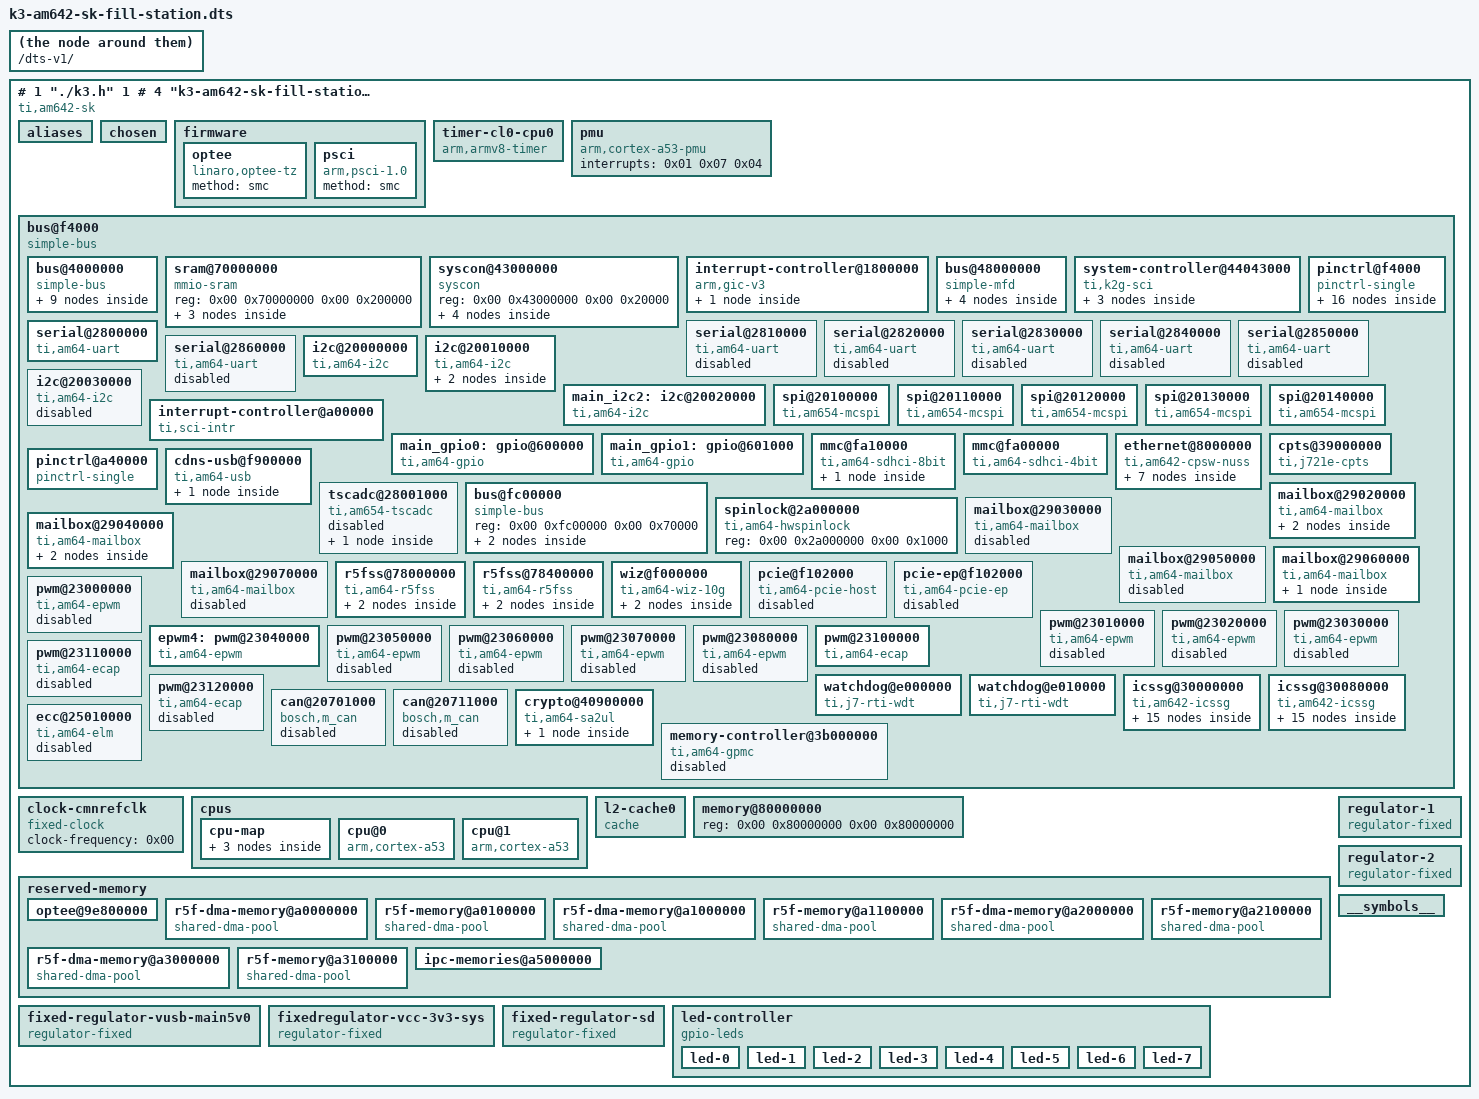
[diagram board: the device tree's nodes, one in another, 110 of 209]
# 1 "k3-am642-sk-fill-station.dts"
# 1 "<built-in>" 1
# 1 "<built-in>" 3
# 10 "<built-in>" 3
# 1 "<command line>" 1
# 1 "<built-in>" 2
# 1 "k3-am642-sk-fill-station.dts" 2
/dts-v1/;

# 1 "./k3.h" 1
# 4 "k3-am642-sk-fill-station.dts" 2

/ {
 model = "Texas Instruments AM642 SK";
 compatible = "ti,am642-sk", "ti,am642";
 interrupt-parent = <0x01>;
 #address-cells = <0x02>;
 #size-cells = <0x02>;

 aliases {
  serial0 = "/bus@f4000/bus@4000000/serial@4a00000";
  serial1 = "/bus@f4000/bus@4000000/serial@4a10000";
  serial2 = "/bus@f4000/serial@2800000";
  serial3 = "/bus@f4000/serial@2810000";
  serial4 = "/bus@f4000/serial@2820000";
  serial5 = "/bus@f4000/serial@2830000";
  serial6 = "/bus@f4000/serial@2840000";
  serial7 = "/bus@f4000/serial@2850000";
  serial8 = "/bus@f4000/serial@2860000";
  ethernet0 = "/bus@f4000/ethernet@8000000/ethernet-ports/port@1";
  ethernet1 = "/bus@f4000/ethernet@8000000/ethernet-ports/port@2";
  mmc0 = "/bus@f4000/mmc@fa10000";
  mmc1 = "/bus@f4000/mmc@fa00000";
 };

 chosen {
  stdout-path = "serial2:115200n8";
  bootargs = "console=ttyS2,115200n8 earlycon=ns16550a,mmio32,0x02800000";
 };

 firmware {

  optee {
   compatible = "linaro,optee-tz";
   method = "smc";
  };

  psci {
   compatible = "arm,psci-1.0";
   method = "smc";
   phandle = <0x3f>;
  };
 };

 timer-cl0-cpu0 {
  compatible = "arm,armv8-timer";
  interrupts = <0x01 0x0d 0x08 0x01 0x0e 0x08 0x01 0x0b 0x08 0x01 0x0a 0x08>;
  phandle = <0x40>;
 };

 pmu {
  compatible = "arm,cortex-a53-pmu";
  interrupts = <0x01 0x07 0x04>;
  phandle = <0x41>;
 };

 bus@f4000 {
  compatible = "simple-bus";
  #address-cells = <0x02>;
  #size-cells = <0x02>;
  ranges = <0x00 0xf4000 0x00 0xf4000 0x00 0x2d0 0x00 0x420000 0x00 0x420000 0x00 0x1000 0x00 0x600000 0x00 0x600000 0x00 0x1100 0x00 0xa40000 0x00 0xa40000 0x00 0x800 0x00 0x1000000 0x00 0x1000000 0x00 0x2330400 0x00 0x8000000 0x00 0x8000000 0x00 0x200000 0x00 0xd000000 0x00 0xd000000 0x00 0x800000 0x00 0xe000000 0x00 0xe000000 0x00 0x100 0x00 0xe010000 0x00 0xe010000 0x00 0x100 0x00 0xf000000 0x00 0xf000000 0x00 0xc44200 0x00 0x20000000 0x00 0x20000000 0x00 0xa008000 0x00 0x30000000 0x00 0x30000000 0x00 0xbc100 0x00 0x37000000 0x00 0x37000000 0x00 0x40000 0x00 0x39000000 0x00 0x39000000 0x00 0x400 0x00 0x3b000000 0x00 0x3b000000 0x00 0x400 0x00 0x3cd00000 0x00 0x3cd00000 0x00 0x200 0x00 0x3f004000 0x00 0x3f004000 0x00 0x400 0x00 0x40900000 0x00 0x40900000 0x00 0x30000 0x00 0x43000000 0x00 0x43000000 0x00 0x20000 0x00 0x44043000 0x00 0x44043000 0x00 0xfe0 0x00 0x48000000 0x00 0x48000000 0x00 0x6400000 0x00 0x50000000 0x00 0x50000000 0x00 0x8000000 0x00 0x60000000 0x00 0x60000000 0x00 0x8000000 0x00 0x68000000 0x00 0x68000000 0x00 0x8000000 0x00 0x70000000 0x00 0x70000000 0x00 0x200000 0x00 0x78000000 0x00 0x78000000 0x00 0x800000 0x01 0x00 0x01 0x00 0x00 0x310000 0x06 0x00 0x06 0x00 0x01 0x00 0x05 0x00 0x05 0x00 0x01 0x00 0x00 0x4000000 0x00 0x4000000 0x00 0x1ff1400>;
  phandle = <0x42>;

  bus@4000000 {
   compatible = "simple-bus";
   #address-cells = <0x02>;
   #size-cells = <0x02>;
   ranges = <0x00 0x4000000 0x00 0x4000000 0x00 0x1ff1400>;
   phandle = <0x43>;

   serial@4a00000 {
    compatible = "ti,am64-uart", "ti,am654-uart";
    reg = <0x00 0x4a00000 0x00 0x100>;
    interrupts = <0x00 0xb9 0x04>;
    current-speed = <0x1c200>;
    power-domains = <0x02 0x95 0x01>;
    clocks = <0x03 0x95 0x00>;
    clock-names = "fclk";
    status = "disabled";
    phandle = <0x44>;
   };

   serial@4a10000 {
    compatible = "ti,am64-uart", "ti,am654-uart";
    reg = <0x00 0x4a10000 0x00 0x100>;
    interrupts = <0x00 0xba 0x04>;
    current-speed = <0x1c200>;
    power-domains = <0x02 0xa0 0x01>;
    clocks = <0x03 0xa0 0x00>;
    clock-names = "fclk";
    status = "disabled";
    phandle = <0x45>;
   };

   i2c@4900000 {
    compatible = "ti,am64-i2c", "ti,omap4-i2c";
    reg = <0x00 0x4900000 0x00 0x100>;
    interrupts = <0x00 0x6b 0x04>;
    #address-cells = <0x01>;
    #size-cells = <0x00>;
    power-domains = <0x02 0x6a 0x01>;
    clocks = <0x03 0x6a 0x02>;
    clock-names = "fck";
    status = "disabled";
    phandle = <0x46>;
   };

   i2c@4910000 {
    compatible = "ti,am64-i2c", "ti,omap4-i2c";
    reg = <0x00 0x4910000 0x00 0x100>;
    interrupts = <0x00 0x6c 0x04>;
    #address-cells = <0x01>;
    #size-cells = <0x00>;
    power-domains = <0x02 0x6b 0x01>;
    clocks = <0x03 0x6b 0x02>;
    clock-names = "fck";
    status = "disabled";
    phandle = <0x47>;
   };

   spi@4b00000 {
    compatible = "ti,am654-mcspi", "ti,omap4-mcspi";
    reg = <0x00 0x4b00000 0x00 0x400>;
    interrupts = <0x00 0xb0 0x04>;
    #address-cells = <0x01>;
    #size-cells = <0x00>;
    power-domains = <0x02 0x93 0x01>;
    clocks = <0x03 0x93 0x00>;
    status = "disabled";
    phandle = <0x48>;
   };

   spi@4b10000 {
    compatible = "ti,am654-mcspi", "ti,omap4-mcspi";
    reg = <0x00 0x4b10000 0x00 0x400>;
    interrupts = <0x00 0xb1 0x04>;
    #address-cells = <0x01>;
    #size-cells = <0x00>;
    power-domains = <0x02 0x94 0x01>;
    clocks = <0x03 0x94 0x00>;
    status = "disabled";
    phandle = <0x49>;
   };

   interrupt-controller@4210000 {
    compatible = "ti,sci-intr";
    reg = <0x00 0x4210000 0x00 0x200>;
    ti,intr-trigger-type = <0x01>;
    interrupt-controller;
    interrupt-parent = <0x01>;
    #interrupt-cells = <0x01>;
    ti,sci = <0x04>;
    ti,sci-dev-id = <0x05>;
    ti,interrupt-ranges = <0x00 0x68 0x04>;
    phandle = <0x05>;
   };

   gpio@4201000 {
    compatible = "ti,am64-gpio", "ti,keystone-gpio";
    reg = <0x00 0x4201000 0x00 0x100>;
    gpio-controller;
    #gpio-cells = <0x02>;
    interrupt-parent = <0x05>;
    interrupts = <0x1e 0x1f>;
    interrupt-controller;
    #interrupt-cells = <0x02>;
    ti,ngpio = <0x17>;
    ti,davinci-gpio-unbanked = <0x00>;
    power-domains = <0x02 0x4f 0x01>;
    clocks = <0x03 0x4f 0x00>;
    clock-names = "gpio";
    status = "reserved";
    phandle = <0x4a>;
   };

   pinctrl@4084000 {
    compatible = "pinctrl-single";
    reg = <0x00 0x4084000 0x00 0x84>;
    #pinctrl-cells = <0x01>;
    pinctrl-single,register-width = <0x20>;
    pinctrl-single,function-mask = <0xffffffff>;
    phandle = <0x4b>;
   };
  };

  sram@70000000 {
   compatible = "mmio-sram";
   reg = <0x00 0x70000000 0x00 0x200000>;
   #address-cells = <0x01>;
   #size-cells = <0x01>;
   ranges = <0x00 0x00 0x70000000 0x200000>;
   phandle = <0x4c>;

   tfa-sram@1c0000 {
    reg = <0x1c0000 0x20000>;
   };

   dmsc-sram@1e0000 {
    reg = <0x1e0000 0x1c000>;
   };

   sproxy-sram@1fc000 {
    reg = <0x1fc000 0x4000>;
   };
  };

  syscon@43000000 {
   compatible = "syscon", "simple-mfd";
   reg = <0x00 0x43000000 0x00 0x20000>;
   #address-cells = <0x01>;
   #size-cells = <0x01>;
   ranges = <0x00 0x00 0x43000000 0x20000>;
   phandle = <0x16>;

   mux-controller {
    compatible = "mmio-mux";
    #mux-control-cells = <0x01>;
    mux-reg-masks = <0x4080 0x03>;
    idle-states = <0x01>;
    phandle = <0x4d>;
   };

   chipid@14 {
    compatible = "ti,am654-chipid";
    reg = <0x14 0x04>;
   };

   phy@4044 {
    compatible = "ti,am654-phy-gmii-sel";
    reg = <0x4044 0x08>;
    #phy-cells = <0x01>;
    phandle = <0x15>;
   };

   clock@4140 {
    compatible = "ti,am64-epwm-tbclk", "syscon";
    reg = <0x4130 0x04>;
    #clock-cells = <0x01>;
    phandle = <0x2f>;
   };
  };

  interrupt-controller@1800000 {
   compatible = "arm,gic-v3";
   #address-cells = <0x02>;
   #size-cells = <0x02>;
   ranges;
   #interrupt-cells = <0x03>;
   interrupt-controller;
   reg = <0x00 0x1800000 0x00 0x10000 0x00 0x1840000 0x00 0xc0000 0x01 0x00 0x00 0x2000 0x01 0x10000 0x00 0x1000 0x01 0x20000 0x00 0x2000>;
   interrupts = <0x01 0x09 0x04>;
   phandle = <0x01>;

   msi-controller@1820000 {
    compatible = "arm,gic-v3-its";
    reg = <0x00 0x1820000 0x00 0x10000>;
    socionext,synquacer-pre-its = <0x1000000 0x400000>;
    msi-controller;
    #msi-cells = <0x01>;
    phandle = <0x2e>;
   };
  };

  bus@48000000 {
   compatible = "simple-mfd";
   #address-cells = <0x02>;
   #size-cells = <0x02>;
   dma-ranges;
   ranges = <0x00 0x48000000 0x00 0x48000000 0x00 0x6400000>;
   ti,sci-dev-id = <0x19>;
   phandle = <0x4e>;

   mailbox@4d000000 {
    compatible = "ti,am654-secure-proxy";
    #mbox-cells = <0x01>;
    reg-names = "target_data", "rt", "scfg";
    reg = <0x00 0x4d000000 0x00 0x80000 0x00 0x4a600000 0x00 0x80000 0x00 0x4a400000 0x00 0x80000>;
    interrupt-names = "rx_012";
    interrupts = <0x00 0x22 0x04>;
    phandle = <0x09>;
   };

   interrupt-controller@48000000 {
    compatible = "ti,sci-inta";
    reg = <0x00 0x48000000 0x00 0x100000>;
    #interrupt-cells = <0x00>;
    interrupt-controller;
    interrupt-parent = <0x01>;
    msi-controller;
    ti,sci = <0x04>;
    ti,sci-dev-id = <0x1c>;
    ti,interrupt-ranges = <0x04 0x44 0x24>;
    ti,unmapped-event-sources = <0x06 0x07>;
    phandle = <0x08>;
   };

   dma-controller@485c0100 {
    compatible = "ti,am64-dmss-bcdma";
    reg = <0x00 0x485c0100 0x00 0x100 0x00 0x4c000000 0x00 0x20000 0x00 0x4a820000 0x00 0x20000 0x00 0x4aa40000 0x00 0x20000 0x00 0x4bc00000 0x00 0x100000>;
    reg-names = "gcfg", "bchanrt", "rchanrt", "tchanrt", "ringrt";
    msi-parent = <0x08>;
    #dma-cells = <0x03>;
    ti,sci = <0x04>;
    ti,sci-dev-id = <0x1a>;
    ti,sci-rm-range-bchan = <0x20>;
    ti,sci-rm-range-rchan = <0x21>;
    ti,sci-rm-range-tchan = <0x22>;
    phandle = <0x06>;
   };

   dma-controller@485c0000 {
    compatible = "ti,am64-dmss-pktdma";
    reg = <0x00 0x485c0000 0x00 0x100 0x00 0x4a800000 0x00 0x20000 0x00 0x4aa00000 0x00 0x40000 0x00 0x4b800000 0x00 0x400000>;
    reg-names = "gcfg", "rchanrt", "tchanrt", "ringrt";
    msi-parent = <0x08>;
    #dma-cells = <0x02>;
    ti,sci = <0x04>;
    ti,sci-dev-id = <0x1e>;
    ti,sci-rm-range-tchan = <0x23 0x24 0x25 0x26 0x27 0x28>;
    ti,sci-rm-range-tflow = <0x10 0x11 0x12 0x13 0x14 0x15>;
    ti,sci-rm-range-rchan = <0x29 0x2b 0x2d 0x2f 0x31 0x33 0x35 0x37>;
    ti,sci-rm-range-rflow = <0x2a 0x2c 0x2e 0x32 0x36 0x38>;
    phandle = <0x07>;
   };
  };

  system-controller@44043000 {
   compatible = "ti,k2g-sci";
   ti,host-id = <0x0c>;
   mbox-names = "rx", "tx";
   mboxes = <0x09 0x0c 0x09 0x0d>;
   reg-names = "debug_messages";
   reg = <0x00 0x44043000 0x00 0xfe0>;
   phandle = <0x04>;

   power-controller {
    compatible = "ti,sci-pm-domain";
    #power-domain-cells = <0x02>;
    phandle = <0x02>;
   };

   clock-controller {
    compatible = "ti,k2g-sci-clk";
    #clock-cells = <0x02>;
    phandle = <0x03>;
   };

   reset-controller {
    compatible = "ti,sci-reset";
    #reset-cells = <0x02>;
    phandle = <0x1c>;
   };
  };

  pinctrl@f4000 {
   compatible = "pinctrl-single";
   reg = <0x00 0xf4000 0x00 0x2d0>;
   #pinctrl-cells = <0x01>;
   pinctrl-single,register-width = <0x20>;
   pinctrl-single,function-mask = <0xffffffff>;
   phandle = <0x4f>;

   main-mmc1-pins-default {
    pinctrl-single,pins = <0x294 0x50000 0x290 0x50000 0x28c 0x50000 0x288 0x50000 0x284 0x50000 0x280 0x50000 0x27c 0x50000 0x298 0x50000>;
    phandle = <0x11>;
   };

   main-uart0-pins-default {
    pinctrl-single,pins = <0x238 0x50000 0x23c 0x10000 0x230 0x50000 0x234 0x10000>;
    phandle = <0x0a>;
   };

   main-usb0-pins-default {
    pinctrl-single,pins = <0x2a8 0x10000>;
    phandle = <0x19>;
   };

   main-i2c1-pins-default {
    pinctrl-single,pins = <0x268 0x60000 0x26c 0x60000>;
    phandle = <0x0b>;
   };

   mdio1-pins-default {
    pinctrl-single,pins = <0x1fc 0x10004 0x1f8 0x50004>;
    phandle = <0x12>;
   };

   rgmii1-pins-default {
    pinctrl-single,pins = <0x11c 0x50004 0x128 0x50004 0x150 0x50004 0x154 0x50004 0xd8 0x50004 0xcc 0x50004 0x124 0x10004 0x12c 0x10004 0x130 0x10004 0x14c 0x10004 0xe0 0x10004 0xdc 0x10004>;
    phandle = <0x13>;
   };

   rgmii2-pins-default {
    pinctrl-single,pins = <0x108 0x50004 0x10c 0x50004 0x110 0x50004 0x114 0x50004 0x120 0x50004 0x118 0x50004 0x134 0x10004 0x138 0x10004 0x13c 0x10004 0x140 0x10004 0x148 0x10004 0x144 0x10004>;
    phandle = <0x14>;
   };

   ospi0-pins-default {
    pinctrl-single,pins = <0x00 0x10000 0x2c 0x10000 0x0c 0x50000 0x10 0x50000 0x14 0x50000 0x18 0x50000 0x1c 0x50000 0x20 0x50000 0x24 0x50000 0x28 0x50000 0x08 0x50000>;
    phandle = <0x1b>;
   };

   main-ecap0-pins-default {
    pinctrl-single,pins = <0x270 0x50000>;
    phandle = <0x30>;
   };

   main-wlan-en-pins-default {
    pinctrl-single,pins = <0xc4 0x20007>;
    phandle = <0x3c>;
   };

   main-com8-ls-en-pins-default {
    pinctrl-single,pins = <0xfc 0x10007>;
    phandle = <0x3b>;
   };

   main-wlan-pins-default {
    pinctrl-single,pins = <0xbc 0x50007>;
    phandle = <0x0e>;
   };

   myepwm1_pins_default: myepwm1-default-pins {
    pinctrl-single,pins = <
     (((0x0088) & 0x1fff)) ((((0 << (18)) | (1 << (16)))) | (3))
    >;
   };

   allgpio0_pins_default: allgpio0-default-pins {
    pinctrl-single,pins = <
     (((0x0084) & 0x1fff)) ((((0 << (18)) | (1 << (16)))) | (7))
     (((0x008c) & 0x1fff)) ((((1 << (18)) | (0 << (17) | (0 << (16))))) | (7))
     (((0x0090) & 0x1fff)) ((((0 << (18)) | (1 << (16)))) | (7))
     (((0x0094) & 0x1fff)) ((((1 << (18)) | (0 << (17) | (0 << (16))))) | (7))
     (((0x0098) & 0x1fff)) ((((0 << (18)) | (1 << (16)))) | (7))
     (((0x00a4) & 0x1fff)) ((((0 << (18)) | (1 << (16)))) | (7))
     (((0x00ac) & 0x1fff)) ((((0 << (18)) | (1 << (17) | (0 << (16))))) | (7))
    >;
   };

   allgpio1_pins_default: allgpio1-default-pins {
    pinctrl-single,pins = <
     (((0x0208) & 0x1fff)) ((((1 << (18)) | (0 << (17) | (0 << (16))))) | (7))
     (((0x020c) & 0x1fff)) ((((1 << (18)) | (0 << (17) | (0 << (16))))) | (7))
     (((0x0214) & 0x1fff)) ((((1 << (18)) | (0 << (17) | (0 << (16))))) | (7))
     (((0x0218) & 0x1fff)) ((((0 << (18)) | (1 << (16)))) | (7))
     (((0x0220) & 0x1fff)) ((((1 << (18)) | (0 << (17) | (0 << (16))))) | (7))
     (((0x022c) & 0x1fff)) ((((1 << (18)) | (0 << (17) | (0 << (16))))) | (7))
     (((0x0258) & 0x1fff)) ((((0 << (18)) | (1 << (16)))) | (7))
     (((0x025c) & 0x1fff)) ((((0 << (18)) | (1 << (16)))) | (7))
     (((0x0260) & 0x1fff)) ((((0 << (18)) | (1 << (16)))) | (7))
     (((0x0264) & 0x1fff)) ((((1 << (18)) | (1 << (16)))) | (7))
    >;
   };

   senseboard_pins_default: senseboard-default-pins {
    pinctrl-single,pins = <
     (((0x00b0) & 0x1fff)) ((((1 << (18)) | (1 << (16)))) | (1))
     (((0x00b4) & 0x1fff)) ((((1 << (18)) | (1 << (16)))) | (1))
    >;
   };

  };

  serial@2800000 {
   compatible = "ti,am64-uart", "ti,am654-uart";
   reg = <0x00 0x2800000 0x00 0x100>;
   interrupts = <0x00 0xb2 0x04>;
   clock-frequency = <0x2dc6c00>;
   current-speed = <0x1c200>;
   power-domains = <0x02 0x92 0x01>;
   clocks = <0x03 0x92 0x00>;
   clock-names = "fclk";
   pinctrl-names = "default";
   pinctrl-0 = <0x0a>;
   phandle = <0x50>;
  };

  serial@2810000 {
   compatible = "ti,am64-uart", "ti,am654-uart";
   reg = <0x00 0x2810000 0x00 0x100>;
   interrupts = <0x00 0xb3 0x04>;
   clock-frequency = <0x2dc6c00>;
   current-speed = <0x1c200>;
   power-domains = <0x02 0x98 0x01>;
   clocks = <0x03 0x98 0x00>;
   clock-names = "fclk";
   status = "reserved";
   phandle = <0x51>;
  };

  serial@2820000 {
   compatible = "ti,am64-uart", "ti,am654-uart";
   reg = <0x00 0x2820000 0x00 0x100>;
   interrupts = <0x00 0xb4 0x04>;
   clock-frequency = <0x2dc6c00>;
   current-speed = <0x1c200>;
   power-domains = <0x02 0x99 0x01>;
   clocks = <0x03 0x99 0x00>;
   clock-names = "fclk";
   status = "disabled";
   phandle = <0x52>;
  };

  serial@2830000 {
   compatible = "ti,am64-uart", "ti,am654-uart";
   reg = <0x00 0x2830000 0x00 0x100>;
   interrupts = <0x00 0xb5 0x04>;
   clock-frequency = <0x2dc6c00>;
   current-speed = <0x1c200>;
   power-domains = <0x02 0x9a 0x01>;
   clocks = <0x03 0x9a 0x00>;
   clock-names = "fclk";
   status = "disabled";
   phandle = <0x53>;
  };

  serial@2840000 {
   compatible = "ti,am64-uart", "ti,am654-uart";
   reg = <0x00 0x2840000 0x00 0x100>;
   interrupts = <0x00 0xb6 0x04>;
   clock-frequency = <0x2dc6c00>;
   current-speed = <0x1c200>;
   power-domains = <0x02 0x9b 0x01>;
   clocks = <0x03 0x9b 0x00>;
   clock-names = "fclk";
   status = "disabled";
   phandle = <0x54>;
  };

  serial@2850000 {
   compatible = "ti,am64-uart", "ti,am654-uart";
   reg = <0x00 0x2850000 0x00 0x100>;
   interrupts = <0x00 0xb7 0x04>;
   clock-frequency = <0x2dc6c00>;
   current-speed = <0x1c200>;
   power-domains = <0x02 0x9c 0x01>;
   clocks = <0x03 0x9c 0x00>;
   clock-names = "fclk";
   status = "disabled";
   phandle = <0x55>;
  };

  serial@2860000 {
   compatible = "ti,am64-uart", "ti,am654-uart";
   reg = <0x00 0x2860000 0x00 0x100>;
   interrupts = <0x00 0xb8 0x04>;
   clock-frequency = <0x2dc6c00>;
   current-speed = <0x1c200>;
   power-domains = <0x02 0x9e 0x01>;
   clocks = <0x03 0x9e 0x00>;
   clock-names = "fclk";
   status = "disabled";
   phandle = <0x56>;
  };

  i2c@20000000 {
   compatible = "ti,am64-i2c", "ti,omap4-i2c";
   reg = <0x00 0x20000000 0x00 0x100>;
   interrupts = <0x00 0xa1 0x04>;
   #address-cells = <0x01>;
   #size-cells = <0x00>;
   power-domains = <0x02 0x66 0x01>;
   clocks = <0x03 0x66 0x02>;
   clock-names = "fck";
   phandle = <0x57>;
  };

  i2c@20010000 {
   compatible = "ti,am64-i2c", "ti,omap4-i2c";
   reg = <0x00 0x20010000 0x00 0x100>;
   interrupts = <0x00 0xa2 0x04>;
   #address-cells = <0x01>;
   #size-cells = <0x00>;
   power-domains = <0x02 0x67 0x01>;
   clocks = <0x03 0x67 0x02>;
   clock-names = "fck";
   pinctrl-names = "default";
   pinctrl-0 = <0x0b>;
   clock-frequency = <0x61a80>;
   phandle = <0x58>;

   gpio@70 {
    compatible = "nxp,pca9538";
    reg = <0x70>;
    gpio-controller;
    #gpio-cells = <0x02>;
    gpio-line-names = "GPIO_CPSW2_RST", "GPIO_CPSW1_RST", "PRU_DETECT", "MMC1_SD_EN", "VPP_LDO_EN", "RPI_PS_3V3_En", "RPI_PS_5V0_En", "RPI_HAT_DETECT";
    phandle = <0x3a>;
   };

   gpio@60 {
    compatible = "ti,tpic2810";
    reg = <0x60>;
    gpio-controller;
    #gpio-cells = <0x02>;
    gpio-line-names = "LED1", "LED2", "LED3", "LED4", "LED5", "LED6", "LED7", "LED8";
    phandle = <0x3e>;
   };
  };

  main_i2c2: i2c@20020000 {
	compatible = "ti,am64-i2c", "ti,omap4-i2c";
	reg = <0x00 0x20020000 0x00 0x100>;
	interrupts = <0x00 0xa3 0x04>;
	#address-cells = <0x01>;
	#size-cells = <0x00>;
	power-domains = <0x02 0x68 0x01>;
	clocks = <0x03 0x68 0x02>;
	clock-names = "fck";

	pinctrl-names = "default";
	pinctrl-0 = <&senseboard_pins_default>;
	status = "okay";
};

  i2c@20030000 {
   compatible = "ti,am64-i2c", "ti,omap4-i2c";
   reg = <0x00 0x20030000 0x00 0x100>;
   interrupts = <0x00 0xa4 0x04>;
   #address-cells = <0x01>;
   #size-cells = <0x00>;
   power-domains = <0x02 0x69 0x01>;
   clocks = <0x03 0x69 0x02>;
   clock-names = "fck";
   status = "disabled";
   phandle = <0x5a>;
  };

  spi@20100000 {
   compatible = "ti,am654-mcspi", "ti,omap4-mcspi";
   reg = <0x00 0x20100000 0x00 0x400>;
   interrupts = <0x00 0xac 0x04>;
   #address-cells = <0x01>;
   #size-cells = <0x00>;
   power-domains = <0x02 0x8d 0x01>;
   clocks = <0x03 0x8d 0x00>;
   dmas = <0x07 0xc300 0x00 0x07 0x4300 0x00>;
   dma-names = "tx0", "rx0";
   phandle = <0x5b>;
  };

  spi@20110000 {
   compatible = "ti,am654-mcspi", "ti,omap4-mcspi";
   reg = <0x00 0x20110000 0x00 0x400>;
   interrupts = <0x00 0xad 0x04>;
   #address-cells = <0x01>;
   #size-cells = <0x00>;
   power-domains = <0x02 0x8e 0x01>;
   clocks = <0x03 0x8e 0x00>;
   phandle = <0x5c>;
  };

  spi@20120000 {
   compatible = "ti,am654-mcspi", "ti,omap4-mcspi";
   reg = <0x00 0x20120000 0x00 0x400>;
   interrupts = <0x00 0xae 0x04>;
   #address-cells = <0x01>;
   #size-cells = <0x00>;
   power-domains = <0x02 0x8f 0x01>;
   clocks = <0x03 0x8f 0x00>;
   phandle = <0x5d>;
  };

  spi@20130000 {
   compatible = "ti,am654-mcspi", "ti,omap4-mcspi";
   reg = <0x00 0x20130000 0x00 0x400>;
   interrupts = <0x00 0x6d 0x04>;
   #address-cells = <0x01>;
   #size-cells = <0x00>;
   power-domains = <0x02 0x90 0x01>;
   clocks = <0x03 0x90 0x00>;
   phandle = <0x5e>;
  };

  spi@20140000 {
   compatible = "ti,am654-mcspi", "ti,omap4-mcspi";
   reg = <0x00 0x20140000 0x00 0x400>;
   interrupts = <0x00 0xaf 0x04>;
   #address-cells = <0x01>;
   #size-cells = <0x00>;
   power-domains = <0x02 0x91 0x01>;
   clocks = <0x03 0x91 0x00>;
   phandle = <0x5f>;
  };

  interrupt-controller@a00000 {
   compatible = "ti,sci-intr";
   reg = <0x00 0xa00000 0x00 0x800>;
   ti,intr-trigger-type = <0x01>;
   interrupt-controller;
   interrupt-parent = <0x01>;
   #interrupt-cells = <0x01>;
   ti,sci = <0x04>;
   ti,sci-dev-id = <0x03>;
   ti,interrupt-ranges = <0x00 0x20 0x10>;
   phandle = <0x0c>;
  };

main_gpio0: gpio@600000 {
	compatible = "ti,am64-gpio", "ti,keystone-gpio";
	reg = <0x00 0x600000 0x00 0x100>;
	gpio-controller;
	#gpio-cells = <0x02>;
	interrupt-parent = <0x0c>;
	interrupts = <0xbe 0xbf 0xc0 0xc1 0xc2 0xc3>;
	interrupt-controller;
	#interrupt-cells = <0x02>;
	ti,ngpio = <0x57>;
	ti,davinci-gpio-unbanked = <0x00>;
	power-domains = <0x02 0x4d 0x01>;
	clocks = <0x03 0x4d 0x00>;
	clock-names = "gpio";

	pinctrl-names = "default";
	pinctrl-0 = <&allgpio0_pins_default>;
};

main_gpio1: gpio@601000 {
	compatible = "ti,am64-gpio", "ti,keystone-gpio";
	reg = <0x00 0x601000 0x00 0x100>;
	gpio-controller;
	#gpio-cells = <0x02>;
	interrupt-parent = <0x0c>;
	interrupts = <0xb4 0xb5 0xb6 0xb7 0xb8 0xb9>;
	interrupt-controller;
	#interrupt-cells = <0x02>;
	ti,ngpio = <0x58>;
	ti,davinci-gpio-unbanked = <0x00>;
	power-domains = <0x02 0x4e 0x01>;
	clocks = <0x03 0x4e 0x00>;
	clock-names = "gpio";

	pinctrl-names = "default";
	pinctrl-0 = <&allgpio1_pins_default>;
};

  mmc@fa10000 {
   compatible = "ti,am64-sdhci-8bit";
   reg = <0x00 0xfa10000 0x00 0x260 0x00 0xfa18000 0x00 0x134>;
   interrupts = <0x00 0x85 0x04>;
   power-domains = <0x02 0x39 0x01>;
   clocks = <0x03 0x39 0x00 0x03 0x39 0x01>;
   clock-names = "clk_ahb", "clk_xin";
   mmc-ddr-1_8v;
   mmc-hs200-1_8v;
   ti,trm-icp = <0x02>;
   ti,otap-del-sel-legacy = <0x00>;
   ti,otap-del-sel-mmc-hs = <0x00>;
   ti,otap-del-sel-ddr52 = <0x06>;
   ti,otap-del-sel-hs200 = <0x07>;
   vmmc-supply = <0x0d>;
   bus-width = <0x04>;
   non-removable;
   cap-power-off-card;
   keep-power-in-suspend;
   ti,driver-strength-ohm = <0x32>;
   #address-cells = <0x01>;
   #size-cells = <0x00>;
   phandle = <0x61>;

   wlcore@2 {
    compatible = "ti,wl1837";
    reg = <0x02>;
    pinctrl-0 = <0x0e>;
    pinctrl-names = "default";
    interrupt-parent = <0x0f>;
    interrupts = <0x2e 0x02>;
    phandle = <0x62>;
   };
  };

  mmc@fa00000 {
   compatible = "ti,am64-sdhci-4bit";
   reg = <0x00 0xfa00000 0x00 0x260 0x00 0xfa08000 0x00 0x134>;
   interrupts = <0x00 0x86 0x04>;
   power-domains = <0x02 0x3a 0x01>;
   clocks = <0x03 0x3a 0x03 0x03 0x3a 0x04>;
   clock-names = "clk_ahb", "clk_xin";
   ti,trm-icp = <0x02>;
   ti,otap-del-sel-legacy = <0x00>;
   ti,otap-del-sel-sd-hs = <0x0f>;
   ti,otap-del-sel-sdr12 = <0x0f>;
   ti,otap-del-sel-sdr25 = <0x0f>;
   ti,otap-del-sel-sdr50 = <0x0c>;
   ti,otap-del-sel-sdr104 = <0x06>;
   ti,otap-del-sel-ddr50 = <0x09>;
   ti,clkbuf-sel = <0x07>;
   vmmc-supply = <0x10>;
   pinctrl-names = "default";
   bus-width = <0x04>;
   pinctrl-0 = <0x11>;
   ti,driver-strength-ohm = <0x32>;
   disable-wp;
   phandle = <0x63>;
  };

  ethernet@8000000 {
   compatible = "ti,am642-cpsw-nuss";
   #address-cells = <0x02>;
   #size-cells = <0x02>;
   reg = <0x00 0x8000000 0x00 0x200000>;
   reg-names = "cpsw_nuss";
   ranges = <0x00 0x00 0x00 0x8000000 0x00 0x200000>;
   clocks = <0x03 0x0d 0x00>;
   assigned-clocks = <0x03 0x0d 0x01>;
   assigned-clock-parents = <0x03 0x0d 0x09>;
   clock-names = "fck";
   power-domains = <0x02 0x0d 0x01>;
   dmas = <0x07 0xc500 0x0f 0x07 0xc501 0x0f 0x07 0xc502 0x0f 0x07 0xc503 0x0f 0x07 0xc504 0x0f 0x07 0xc505 0x0f 0x07 0xc506 0x0f 0x07 0xc507 0x0f 0x07 0x4500 0x0f>;
   dma-names = "tx0", "tx1", "tx2", "tx3", "tx4", "tx5", "tx6", "tx7", "rx";
   pinctrl-names = "default";
   pinctrl-0 = <0x12 0x13 0x14>;
   phandle = <0x64>;

   ethernet-ports {
    #address-cells = <0x01>;
    #size-cells = <0x00>;

    port@1 {
     reg = <0x01>;
     ti,mac-only;
     label = "port1";
     phys = <0x15 0x01>;
     mac-address = [00 00 00 00 00 00];
     ti,syscon-efuse = <0x16 0x200>;
     phy-mode = "rgmii-rxid";
     phy-handle = <0x17>;
     phandle = <0x65>;
    };

    port@2 {
     reg = <0x02>;
     ti,mac-only;
     label = "port2";
     phys = <0x15 0x02>;
     mac-address = [00 00 00 00 00 00];
     phy-mode = "rgmii-rxid";
     phy-handle = <0x18>;
     phandle = <0x66>;
    };
   };

   mdio@f00 {
    compatible = "ti,cpsw-mdio", "ti,davinci_mdio";
    reg = <0x00 0xf00 0x00 0x100>;
    #address-cells = <0x01>;
    #size-cells = <0x00>;
    clocks = <0x03 0x0d 0x00>;
    clock-names = "fck";
    bus_freq = <0xf4240>;
    phandle = <0x67>;

    ethernet-phy@0 {
     reg = <0x00>;
     ti,rx-internal-delay = <0x07>;
     ti,fifo-depth = <0x01>;
     phandle = <0x17>;
    };

    ethernet-phy@1 {
     reg = <0x01>;
     ti,rx-internal-delay = <0x07>;
     ti,fifo-depth = <0x01>;
     phandle = <0x18>;
    };
   };

   cpts@3d000 {
    compatible = "ti,j721e-cpts";
    reg = <0x00 0x3d000 0x00 0x400>;
    clocks = <0x03 0x0d 0x01>;
    clock-names = "cpts";
    interrupts-extended = <0x01 0x00 0x66 0x04>;
    interrupt-names = "cpts";
    ti,cpts-ext-ts-inputs = <0x04>;
    ti,cpts-periodic-outputs = <0x02>;
   };
  };

  cpts@39000000 {
   compatible = "ti,j721e-cpts";
   reg = <0x00 0x39000000 0x00 0x400>;
   reg-names = "cpts";
   power-domains = <0x02 0x54 0x01>;
   clocks = <0x03 0x54 0x00>;
   clock-names = "cpts";
   assigned-clocks = <0x03 0x54 0x00>;
   assigned-clock-parents = <0x03 0x54 0x08>;
   interrupts = <0x00 0x61 0x04>;
   interrupt-names = "cpts";
   ti,cpts-periodic-outputs = <0x06>;
   ti,cpts-ext-ts-inputs = <0x08>;
   phandle = <0x68>;
  };

  pinctrl@a40000 {
   compatible = "pinctrl-single";
   reg = <0x00 0xa40000 0x00 0x800>;
   #pinctrl-cells = <0x01>;
   pinctrl-single,register-width = <0x20>;
   pinctrl-single,function-mask = <0x107ff>;
   phandle = <0x69>;
  };

  cdns-usb@f900000 {
   compatible = "ti,am64-usb";
   reg = <0x00 0xf900000 0x00 0x100>;
   power-domains = <0x02 0xa1 0x01>;
   clocks = <0x03 0xa1 0x09 0x03 0xa1 0x01>;
   clock-names = "ref", "lpm";
   assigned-clocks = <0x03 0xa1 0x09>;
   assigned-clock-parents = <0x03 0xa1 0x0a>;
   #address-cells = <0x02>;
   #size-cells = <0x02>;
   ranges;
   ti,vbus-divider;
   phandle = <0x6a>;

   usb@f400000 {
    compatible = "cdns,usb3";
    reg = <0x00 0xf400000 0x00 0x10000 0x00 0xf410000 0x00 0x10000 0x00 0xf420000 0x00 0x10000>;
    reg-names = "otg", "xhci", "dev";
    interrupts = <0x00 0xbc 0x04 0x00 0xc2 0x04 0x00 0xc4 0x04>;
    interrupt-names = "host", "peripheral", "otg";
    maximum-speed = "super-speed";
    dr_mode = "host";
    pinctrl-names = "default";
    pinctrl-0 = <0x19>;
    phys = <0x1a>;
    phy-names = "cdns3,usb3-phy";
    phandle = <0x6b>;
   };
  };

  tscadc@28001000 {
   compatible = "ti,am654-tscadc", "ti,am3359-tscadc";
   reg = <0x00 0x28001000 0x00 0x1000>;
   interrupts = <0x00 0x60 0x04>;
   power-domains = <0x02 0x00 0x01>;
   clocks = <0x03 0x00 0x00>;
   assigned-clocks = <0x03 0x00 0x00>;
   assigned-clock-parents = <0x03 0x00 0x03>;
   assigned-clock-rates = <0x3938700>;
   clock-names = "adc_tsc_fck";
   status = "disabled";
   phandle = <0x6c>;

   adc {
    #io-channel-cells = <0x01>;
    compatible = "ti,am654-adc", "ti,am3359-adc";
   };
  };

  bus@fc00000 {
   compatible = "simple-bus";
   reg = <0x00 0xfc00000 0x00 0x70000>;
   #address-cells = <0x02>;
   #size-cells = <0x02>;
   ranges;
   phandle = <0x6d>;

   spi@fc40000 {
    compatible = "ti,am654-ospi", "cdns,qspi-nor";
    reg = <0x00 0xfc40000 0x00 0x100 0x05 0x00 0x01 0x00>;
    interrupts = <0x00 0x8b 0x04>;
    cdns,fifo-depth = <0x100>;
    cdns,fifo-width = <0x04>;
    cdns,trigger-address = <0x00>;
    #address-cells = <0x01>;
    #size-cells = <0x00>;
    clocks = <0x03 0x4b 0x06>;
    assigned-clocks = <0x03 0x4b 0x06>;
    assigned-clock-parents = <0x03 0x4b 0x07>;
    assigned-clock-rates = <0x9ef21aa>;
    power-domains = <0x02 0x4b 0x01>;
    pinctrl-names = "default";
    pinctrl-0 = <0x1b>;
    phandle = <0x6e>;

    flash@0 {
     compatible = "jedec,spi-nor";
     reg = <0x00>;
     spi-tx-bus-width = <0x08>;
     spi-rx-bus-width = <0x08>;
     spi-max-frequency = <0x17d7840>;
     cdns,tshsl-ns = <0x3c>;
     cdns,tsd2d-ns = <0x3c>;
     cdns,tchsh-ns = <0x3c>;
     cdns,tslch-ns = <0x3c>;
     cdns,read-delay = <0x04>;
    };
   };
  };

  spinlock@2a000000 {
   compatible = "ti,am64-hwspinlock";
   reg = <0x00 0x2a000000 0x00 0x1000>;
   #hwlock-cells = <0x01>;
   phandle = <0x6f>;
  };

  mailbox@29020000 {
   compatible = "ti,am64-mailbox";
   reg = <0x00 0x29020000 0x00 0x200>;
   interrupts = <0x00 0x50 0x04 0x00 0x51 0x04>;
   #mbox-cells = <0x01>;
   ti,mbox-num-users = <0x04>;
   ti,mbox-num-fifos = <0x10>;
   phandle = <0x1d>;

   mbox-main-r5fss0-core0 {
    ti,mbox-rx = <0x00 0x00 0x02>;
    ti,mbox-tx = <0x01 0x00 0x02>;
    phandle = <0x1e>;
   };

   mbox-main-r5fss0-core1 {
    ti,mbox-rx = <0x02 0x00 0x02>;
    ti,mbox-tx = <0x03 0x00 0x02>;
    phandle = <0x21>;
   };
  };

  mailbox@29030000 {
   compatible = "ti,am64-mailbox";
   reg = <0x00 0x29030000 0x00 0x200>;
   interrupts = <0x00 0x52 0x04 0x00 0x53 0x04>;
   #mbox-cells = <0x01>;
   ti,mbox-num-users = <0x04>;
   ti,mbox-num-fifos = <0x10>;
   status = "disabled";
   phandle = <0x70>;
  };

  mailbox@29040000 {
   compatible = "ti,am64-mailbox";
   reg = <0x00 0x29040000 0x00 0x200>;
   interrupts = <0x00 0x54 0x04 0x00 0x55 0x04>;
   #mbox-cells = <0x01>;
   ti,mbox-num-users = <0x04>;
   ti,mbox-num-fifos = <0x10>;
   phandle = <0x24>;

   mbox-main-r5fss1-core0 {
    ti,mbox-rx = <0x00 0x00 0x02>;
    ti,mbox-tx = <0x01 0x00 0x02>;
    phandle = <0x25>;
   };

   mbox-main-r5fss1-core1 {
    ti,mbox-rx = <0x02 0x00 0x02>;
    ti,mbox-tx = <0x03 0x00 0x02>;
    phandle = <0x28>;
   };
  };

  mailbox@29050000 {
   compatible = "ti,am64-mailbox";
   reg = <0x00 0x29050000 0x00 0x200>;
   interrupts = <0x00 0x56 0x04 0x00 0x57 0x04>;
   #mbox-cells = <0x01>;
   ti,mbox-num-users = <0x04>;
   ti,mbox-num-fifos = <0x10>;
   status = "disabled";
   phandle = <0x71>;
  };

  mailbox@29060000 {
   compatible = "ti,am64-mailbox";
   reg = <0x00 0x29060000 0x00 0x200>;
   interrupts = <0x00 0x4c 0x04>;
   #mbox-cells = <0x01>;
   ti,mbox-num-users = <0x04>;
   ti,mbox-num-fifos = <0x10>;
   phandle = <0x72>;

   mbox-m4-0 {
    ti,mbox-rx = <0x00 0x00 0x02>;
    ti,mbox-tx = <0x01 0x00 0x02>;
    phandle = <0x73>;
   };
  };

  mailbox@29070000 {
   compatible = "ti,am64-mailbox";
   reg = <0x00 0x29070000 0x00 0x200>;
   interrupts = <0x00 0x4d 0x04>;
   #mbox-cells = <0x01>;
   ti,mbox-num-users = <0x04>;
   ti,mbox-num-fifos = <0x10>;
   status = "disabled";
   phandle = <0x74>;
  };

  r5fss@78000000 {
   compatible = "ti,am64-r5fss";
   ti,cluster-mode = <0x00>;
   #address-cells = <0x01>;
   #size-cells = <0x01>;
   ranges = <0x78000000 0x00 0x78000000 0x10000 0x78100000 0x00 0x78100000 0x10000 0x78200000 0x00 0x78200000 0x8000 0x78300000 0x00 0x78300000 0x8000>;
   power-domains = <0x02 0x77 0x01>;
   phandle = <0x75>;

   r5f@78000000 {
    compatible = "ti,am64-r5f";
    reg = <0x78000000 0x10000 0x78100000 0x10000>;
    reg-names = "atcm", "btcm";
    ti,sci = <0x04>;
    ti,sci-dev-id = <0x79>;
    ti,sci-proc-ids = <0x01 0xff>;
    resets = <0x1c 0x79 0x01>;
    firmware-name = "am64-main-r5f0_0-fw";
    ti,atcm-enable = <0x01>;
    ti,btcm-enable = <0x01>;
    ti,loczrama = <0x01>;
    mboxes = <0x1d 0x1e>;
    memory-region = <0x1f 0x20>;
    phandle = <0x76>;
   };

   r5f@78200000 {
    compatible = "ti,am64-r5f";
    reg = <0x78200000 0x8000 0x78300000 0x8000>;
    reg-names = "atcm", "btcm";
    ti,sci = <0x04>;
    ti,sci-dev-id = <0x7a>;
    ti,sci-proc-ids = <0x02 0xff>;
    resets = <0x1c 0x7a 0x01>;
    firmware-name = "am64-main-r5f0_1-fw";
    ti,atcm-enable = <0x01>;
    ti,btcm-enable = <0x01>;
    ti,loczrama = <0x01>;
    mboxes = <0x1d 0x21>;
    memory-region = <0x22 0x23>;
    phandle = <0x77>;
   };
  };

  r5fss@78400000 {
   compatible = "ti,am64-r5fss";
   ti,cluster-mode = <0x00>;
   #address-cells = <0x01>;
   #size-cells = <0x01>;
   ranges = <0x78400000 0x00 0x78400000 0x10000 0x78500000 0x00 0x78500000 0x10000 0x78600000 0x00 0x78600000 0x8000 0x78700000 0x00 0x78700000 0x8000>;
   power-domains = <0x02 0x78 0x01>;
   phandle = <0x78>;

   r5f@78400000 {
    compatible = "ti,am64-r5f";
    reg = <0x78400000 0x10000 0x78500000 0x10000>;
    reg-names = "atcm", "btcm";
    ti,sci = <0x04>;
    ti,sci-dev-id = <0x7b>;
    ti,sci-proc-ids = <0x06 0xff>;
    resets = <0x1c 0x7b 0x01>;
    firmware-name = "am64-main-r5f1_0-fw";
    ti,atcm-enable = <0x01>;
    ti,btcm-enable = <0x01>;
    ti,loczrama = <0x01>;
    mboxes = <0x24 0x25>;
    memory-region = <0x26 0x27>;
    phandle = <0x79>;
   };

   r5f@78600000 {
    compatible = "ti,am64-r5f";
    reg = <0x78600000 0x8000 0x78700000 0x8000>;
    reg-names = "atcm", "btcm";
    ti,sci = <0x04>;
    ti,sci-dev-id = <0x7c>;
    ti,sci-proc-ids = <0x07 0xff>;
    resets = <0x1c 0x7c 0x01>;
    firmware-name = "am64-main-r5f1_1-fw";
    ti,atcm-enable = <0x01>;
    ti,btcm-enable = <0x01>;
    ti,loczrama = <0x01>;
    mboxes = <0x24 0x28>;
    memory-region = <0x29 0x2a>;
    phandle = <0x7a>;
   };
  };

  wiz@f000000 {
   compatible = "ti,am64-wiz-10g";
   #address-cells = <0x01>;
   #size-cells = <0x01>;
   power-domains = <0x02 0xa2 0x01>;
   clocks = <0x03 0xa2 0x00 0x03 0xa2 0x01 0x2b>;
   clock-names = "fck", "core_ref_clk", "ext_ref_clk";
   num-lanes = <0x01>;
   #reset-cells = <0x01>;
   #clock-cells = <0x01>;
   ranges = <0xf000000 0x00 0xf000000 0x10000>;
   assigned-clocks = <0x03 0xa2 0x01>;
   assigned-clock-parents = <0x03 0xa2 0x05>;
   phandle = <0x2c>;

   serdes@f000000 {
    compatible = "ti,j721e-serdes-10g";
    reg = <0xf000000 0x10000>;
    reg-names = "torrent_phy";
    resets = <0x2c 0x00>;
    reset-names = "torrent_reset";
    clocks = <0x2c 0x00 0x2c 0x10>;
    clock-names = "refclk", "phy_en_refclk";
    assigned-clocks = <0x2c 0x00 0x2c 0x01 0x2c 0x02>;
    assigned-clock-parents = <0x03 0xa2 0x01 0x03 0xa2 0x01 0x03 0xa2 0x01>;
    #address-cells = <0x01>;
    #size-cells = <0x00>;
    #clock-cells = <0x01>;
    phandle = <0x2d>;

    phy@0 {
     reg = <0x00>;
     cdns,num-lanes = <0x01>;
     #phy-cells = <0x00>;
     cdns,phy-type = <0x04>;
     resets = <0x2c 0x01>;
     phandle = <0x1a>;
    };
   };
  };

  pcie@f102000 {
   compatible = "ti,am64-pcie-host", "ti,j721e-pcie-host";
   reg = <0x00 0xf102000 0x00 0x1000 0x00 0xf100000 0x00 0x400 0x00 0xd000000 0x00 0x800000 0x00 0x68000000 0x00 0x1000>;
   reg-names = "intd_cfg", "user_cfg", "reg", "cfg";
   interrupt-names = "link_state";
   interrupts = <0x00 0xcb 0x01>;
   device_type = "pci";
   ti,syscon-pcie-ctrl = <0x16 0x4070>;
   max-link-speed = <0x02>;
   num-lanes = <0x01>;
   power-domains = <0x02 0x72 0x01>;
   clocks = <0x03 0x72 0x00 0x2d 0x00>;
   clock-names = "fck", "pcie_refclk";
   #address-cells = <0x03>;
   #size-cells = <0x02>;
   bus-range = <0x00 0xff>;
   cdns,no-bar-match-nbits = <0x40>;
   vendor-id = <0x104c>;
   device-id = <0xb010>;
   msi-map = <0x00 0x2e 0x00 0x10000>;
   ranges = <0x1000000 0x00 0x68001000 0x00 0x68001000 0x00 0x10000 0x2000000 0x00 0x68011000 0x00 0x68011000 0x00 0x7fef000>;
   dma-ranges = <0x2000000 0x00 0x00 0x00 0x00 0x10 0x00>;
   status = "disabled";
   phandle = <0x7b>;
  };

  pcie-ep@f102000 {
   compatible = "ti,am64-pcie-ep", "ti,j721e-pcie-ep";
   reg = <0x00 0xf102000 0x00 0x1000 0x00 0xf100000 0x00 0x400 0x00 0xd000000 0x00 0x800000 0x00 0x68000000 0x00 0x8000000>;
   reg-names = "intd_cfg", "user_cfg", "reg", "mem";
   interrupt-names = "link_state";
   interrupts = <0x00 0xcb 0x01>;
   ti,syscon-pcie-ctrl = <0x16 0x4070>;
   max-link-speed = <0x02>;
   num-lanes = <0x01>;
   power-domains = <0x02 0x72 0x01>;
   clocks = <0x03 0x72 0x00>;
   clock-names = "fck";
   max-functions = [01];
   status = "disabled";
   phandle = <0x7c>;
  };

  pwm@23000000 {
   compatible = "ti,am64-epwm", "ti,am3352-ehrpwm";
   #pwm-cells = <0x03>;
   reg = <0x00 0x23000000 0x00 0x100>;
   power-domains = <0x02 0x56 0x01>;
   clocks = <0x2f 0x00 0x03 0x56 0x00>;
   clock-names = "tbclk", "fck";
   status = "disabled";
   phandle = <0x7d>;
  };

  pwm@23010000 {
   compatible = "ti,am64-epwm", "ti,am3352-ehrpwm";
   #pwm-cells = <0x03>;
   reg = <0x00 0x23010000 0x00 0x100>;
   power-domains = <0x02 0x57 0x01>;
   clocks = <0x2f 0x01 0x03 0x57 0x00>;
   clock-names = "tbclk", "fck";
   status = "disabled";
   phandle = <0x7e>;
  };

  pwm@23020000 {
   compatible = "ti,am64-epwm", "ti,am3352-ehrpwm";
   #pwm-cells = <0x03>;
   reg = <0x00 0x23020000 0x00 0x100>;
   power-domains = <0x02 0x58 0x01>;
   clocks = <0x2f 0x02 0x03 0x58 0x00>;
   clock-names = "tbclk", "fck";
   status = "disabled";
   phandle = <0x7f>;
  };

  pwm@23030000 {
   compatible = "ti,am64-epwm", "ti,am3352-ehrpwm";
   #pwm-cells = <0x03>;
   reg = <0x00 0x23030000 0x00 0x100>;
   power-domains = <0x02 0x59 0x01>;
   clocks = <0x2f 0x03 0x03 0x59 0x00>;
   clock-names = "tbclk", "fck";
   status = "disabled";
   phandle = <0x80>;
  };

epwm4: pwm@23040000 {
	compatible = "ti,am64-epwm", "ti,am3352-ehrpwm";
	#pwm-cells = <0x03>;
	reg = <0x00 0x23040000 0x00 0x100>;
	power-domains = <0x02 0x5a 0x01>;
	clocks = <0x2f 0x04 0x03 0x5a 0x00>;
	clock-names = "tbclk", "fck";

	pinctrl-names = "default";
	pinctrl-0 = <&myepwm1_pins_default>;
	status = "okay";
};

  pwm@23050000 {
   compatible = "ti,am64-epwm", "ti,am3352-ehrpwm";
   #pwm-cells = <0x03>;
   reg = <0x00 0x23050000 0x00 0x100>;
   power-domains = <0x02 0x5b 0x01>;
   clocks = <0x2f 0x05 0x03 0x5b 0x00>;
   clock-names = "tbclk", "fck";
   status = "disabled";
   phandle = <0x82>;
  };

  pwm@23060000 {
   compatible = "ti,am64-epwm", "ti,am3352-ehrpwm";
   #pwm-cells = <0x03>;
   reg = <0x00 0x23060000 0x00 0x100>;
   power-domains = <0x02 0x5c 0x01>;
   clocks = <0x2f 0x06 0x03 0x5c 0x00>;
   clock-names = "tbclk", "fck";
   status = "disabled";
   phandle = <0x83>;
  };

  pwm@23070000 {
   compatible = "ti,am64-epwm", "ti,am3352-ehrpwm";
   #pwm-cells = <0x03>;
   reg = <0x00 0x23070000 0x00 0x100>;
   power-domains = <0x02 0x5d 0x01>;
   clocks = <0x2f 0x07 0x03 0x5d 0x00>;
   clock-names = "tbclk", "fck";
   status = "disabled";
   phandle = <0x84>;
  };

  pwm@23080000 {
   compatible = "ti,am64-epwm", "ti,am3352-ehrpwm";
   #pwm-cells = <0x03>;
   reg = <0x00 0x23080000 0x00 0x100>;
   power-domains = <0x02 0x5e 0x01>;
   clocks = <0x2f 0x08 0x03 0x5e 0x00>;
   clock-names = "tbclk", "fck";
   status = "disabled";
   phandle = <0x85>;
  };

  pwm@23100000 {
   compatible = "ti,am64-ecap", "ti,am3352-ecap";
   #pwm-cells = <0x03>;
   reg = <0x00 0x23100000 0x00 0x60>;
   power-domains = <0x02 0x33 0x01>;
   clocks = <0x03 0x33 0x00>;
   clock-names = "fck";
   pinctrl-names = "default";
   pinctrl-0 = <0x30>;
   phandle = <0x86>;
  };

  pwm@23110000 {
   compatible = "ti,am64-ecap", "ti,am3352-ecap";
   #pwm-cells = <0x03>;
   reg = <0x00 0x23110000 0x00 0x60>;
   power-domains = <0x02 0x34 0x01>;
   clocks = <0x03 0x34 0x00>;
   clock-names = "fck";
   status = "disabled";
   phandle = <0x87>;
  };

  pwm@23120000 {
   compatible = "ti,am64-ecap", "ti,am3352-ecap";
   #pwm-cells = <0x03>;
   reg = <0x00 0x23120000 0x00 0x60>;
   power-domains = <0x02 0x35 0x01>;
   clocks = <0x03 0x35 0x00>;
   clock-names = "fck";
   status = "disabled";
   phandle = <0x88>;
  };

  watchdog@e000000 {
   compatible = "ti,j7-rti-wdt";
   reg = <0x00 0xe000000 0x00 0x100>;
   clocks = <0x03 0x7d 0x00>;
   power-domains = <0x02 0x7d 0x01>;
   assigned-clocks = <0x03 0x7d 0x00>;
   assigned-clock-parents = <0x03 0x7d 0x02>;
   phandle = <0x89>;
  };

  watchdog@e010000 {
   compatible = "ti,j7-rti-wdt";
   reg = <0x00 0xe010000 0x00 0x100>;
   clocks = <0x03 0x7e 0x00>;
   power-domains = <0x02 0x7e 0x01>;
   assigned-clocks = <0x03 0x7e 0x00>;
   assigned-clock-parents = <0x03 0x7e 0x02>;
   phandle = <0x8a>;
  };

  icssg@30000000 {
   compatible = "ti,am642-icssg";
   reg = <0x00 0x30000000 0x00 0x80000>;
   power-domains = <0x02 0x51 0x01>;
   #address-cells = <0x01>;
   #size-cells = <0x01>;
   ranges = <0x00 0x00 0x30000000 0x80000>;
   phandle = <0x8b>;

   memories@0 {
    reg = <0x00 0x2000 0x2000 0x2000 0x10000 0x10000>;
    reg-names = "dram0", "dram1", "shrdram2";
    phandle = <0x8c>;
   };

   cfg@26000 {
    compatible = "ti,pruss-cfg", "syscon";
    reg = <0x26000 0x200>;
    #address-cells = <0x01>;
    #size-cells = <0x01>;
    ranges = <0x00 0x26000 0x2000>;
    phandle = <0x8d>;

    clocks {
     #address-cells = <0x01>;
     #size-cells = <0x00>;

     coreclk-mux@3c {
      reg = <0x3c>;
      #clock-cells = <0x00>;
      clocks = <0x03 0x51 0x00 0x03 0x51 0x14>;
      assigned-clocks = <0x31>;
      assigned-clock-parents = <0x03 0x51 0x14>;
      phandle = <0x31>;
     };

     iepclk-mux@30 {
      reg = <0x30>;
      #clock-cells = <0x00>;
      clocks = <0x03 0x51 0x03 0x31>;
      assigned-clocks = <0x32>;
      assigned-clock-parents = <0x31>;
      phandle = <0x32>;
     };
    };
   };

   mii-rt@32000 {
    compatible = "ti,pruss-mii", "syscon";
    reg = <0x32000 0x100>;
    phandle = <0x8e>;
   };

   mii-g-rt@33000 {
    compatible = "ti,pruss-mii-g", "syscon";
    reg = <0x33000 0x1000>;
    phandle = <0x8f>;
   };

   interrupt-controller@20000 {
    compatible = "ti,icssg-intc";
    reg = <0x20000 0x2000>;
    interrupt-controller;
    #interrupt-cells = <0x03>;
    interrupts = <0x00 0x58 0x04 0x00 0x59 0x04 0x00 0x5a 0x04 0x00 0x5b 0x04 0x00 0x5c 0x04 0x00 0x5d 0x04 0x00 0x5e 0x04 0x00 0x5f 0x04>;
    interrupt-names = "host_intr0", "host_intr1", "host_intr2", "host_intr3", "host_intr4", "host_intr5", "host_intr6", "host_intr7";
    phandle = <0x90>;
   };

   pru@34000 {
    compatible = "ti,am642-pru";
    reg = <0x34000 0x3000 0x22000 0x100 0x22400 0x100>;
    reg-names = "iram", "control", "debug";
    firmware-name = "am64x-pru0_0-fw";
    phandle = <0x91>;
   };

   rtu@4000 {
    compatible = "ti,am642-rtu";
    reg = <0x4000 0x2000 0x23000 0x100 0x23400 0x100>;
    reg-names = "iram", "control", "debug";
    firmware-name = "am64x-rtu0_0-fw";
    phandle = <0x92>;
   };

   txpru@a000 {
    compatible = "ti,am642-tx-pru";
    reg = <0xa000 0x1800 0x25000 0x100 0x25400 0x100>;
    reg-names = "iram", "control", "debug";
    firmware-name = "am64x-txpru0_0-fw";
    phandle = <0x93>;
   };

   pru@38000 {
    compatible = "ti,am642-pru";
    reg = <0x38000 0x3000 0x24000 0x100 0x24400 0x100>;
    reg-names = "iram", "control", "debug";
    firmware-name = "am64x-pru0_1-fw";
    phandle = <0x94>;
   };

   rtu@6000 {
    compatible = "ti,am642-rtu";
    reg = <0x6000 0x2000 0x23800 0x100 0x23c00 0x100>;
    reg-names = "iram", "control", "debug";
    firmware-name = "am64x-rtu0_1-fw";
    phandle = <0x95>;
   };

   txpru@c000 {
    compatible = "ti,am642-tx-pru";
    reg = <0xc000 0x1800 0x25800 0x100 0x25c00 0x100>;
    reg-names = "iram", "control", "debug";
    firmware-name = "am64x-txpru0_1-fw";
    phandle = <0x96>;
   };

   mdio@32400 {
    compatible = "ti,davinci_mdio";
    reg = <0x32400 0x100>;
    clocks = <0x03 0x3e 0x03>;
    clock-names = "fck";
    #address-cells = <0x01>;
    #size-cells = <0x00>;
    bus_freq = <0xf4240>;
    status = "disabled";
    phandle = <0x97>;
   };
  };

  icssg@30080000 {
   compatible = "ti,am642-icssg";
   reg = <0x00 0x30080000 0x00 0x80000>;
   power-domains = <0x02 0x52 0x01>;
   #address-cells = <0x01>;
   #size-cells = <0x01>;
   ranges = <0x00 0x00 0x30080000 0x80000>;
   phandle = <0x98>;

   memories@0 {
    reg = <0x00 0x2000 0x2000 0x2000 0x10000 0x10000>;
    reg-names = "dram0", "dram1", "shrdram2";
    phandle = <0x99>;
   };

   cfg@26000 {
    compatible = "ti,pruss-cfg", "syscon";
    reg = <0x26000 0x200>;
    #address-cells = <0x01>;
    #size-cells = <0x01>;
    ranges = <0x00 0x26000 0x2000>;
    phandle = <0x9a>;

    clocks {
     #address-cells = <0x01>;
     #size-cells = <0x00>;

     coreclk-mux@3c {
      reg = <0x3c>;
      #clock-cells = <0x00>;
      clocks = <0x03 0x52 0x00 0x03 0x52 0x14>;
      assigned-clocks = <0x33>;
      assigned-clock-parents = <0x03 0x52 0x14>;
      phandle = <0x33>;
     };

     iepclk-mux@30 {
      reg = <0x30>;
      #clock-cells = <0x00>;
      clocks = <0x03 0x52 0x03 0x33>;
      assigned-clocks = <0x34>;
      assigned-clock-parents = <0x33>;
      phandle = <0x34>;
     };
    };
   };

   mii-rt@32000 {
    compatible = "ti,pruss-mii", "syscon";
    reg = <0x32000 0x100>;
    phandle = <0x9b>;
   };

   mii-g-rt@33000 {
    compatible = "ti,pruss-mii-g", "syscon";
    reg = <0x33000 0x1000>;
    phandle = <0x9c>;
   };

   interrupt-controller@20000 {
    compatible = "ti,icssg-intc";
    reg = <0x20000 0x2000>;
    interrupt-controller;
    #interrupt-cells = <0x03>;
    interrupts = <0x00 0xd8 0x04 0x00 0xd9 0x04 0x00 0xda 0x04 0x00 0xdb 0x04 0x00 0xdc 0x04 0x00 0xdd 0x04 0x00 0xde 0x04 0x00 0xdf 0x04>;
    interrupt-names = "host_intr0", "host_intr1", "host_intr2", "host_intr3", "host_intr4", "host_intr5", "host_intr6", "host_intr7";
    phandle = <0x9d>;
   };

   pru@34000 {
    compatible = "ti,am642-pru";
    reg = <0x34000 0x4000 0x22000 0x100 0x22400 0x100>;
    reg-names = "iram", "control", "debug";
    firmware-name = "am64x-pru1_0-fw";
    phandle = <0x9e>;
   };

   rtu@4000 {
    compatible = "ti,am642-rtu";
    reg = <0x4000 0x2000 0x23000 0x100 0x23400 0x100>;
    reg-names = "iram", "control", "debug";
    firmware-name = "am64x-rtu1_0-fw";
    phandle = <0x9f>;
   };

   txpru@a000 {
    compatible = "ti,am642-tx-pru";
    reg = <0xa000 0x1800 0x25000 0x100 0x25400 0x100>;
    reg-names = "iram", "control", "debug";
    firmware-name = "am64x-txpru1_0-fw";
    phandle = <0xa0>;
   };

   pru@38000 {
    compatible = "ti,am642-pru";
    reg = <0x38000 0x4000 0x24000 0x100 0x24400 0x100>;
    reg-names = "iram", "control", "debug";
    firmware-name = "am64x-pru1_1-fw";
    phandle = <0xa1>;
   };

   rtu@6000 {
    compatible = "ti,am642-rtu";
    reg = <0x6000 0x2000 0x23800 0x100 0x23c00 0x100>;
    reg-names = "iram", "control", "debug";
    firmware-name = "am64x-rtu1_1-fw";
    phandle = <0xa2>;
   };

   txpru@c000 {
    compatible = "ti,am642-tx-pru";
    reg = <0xc000 0x1800 0x25800 0x100 0x25c00 0x100>;
    reg-names = "iram", "control", "debug";
    firmware-name = "am64x-txpru1_1-fw";
    phandle = <0xa3>;
   };

   mdio@32400 {
    compatible = "ti,davinci_mdio";
    reg = <0x32400 0x100>;
    #address-cells = <0x01>;
    #size-cells = <0x00>;
    clocks = <0x03 0x52 0x00>;
    clock-names = "fck";
    bus_freq = <0xf4240>;
    status = "disabled";
    phandle = <0xa4>;
   };
  };

  can@20701000 {
   compatible = "bosch,m_can";
   reg = <0x00 0x20701000 0x00 0x200 0x00 0x20708000 0x00 0x8000>;
   reg-names = "m_can", "message_ram";
   power-domains = <0x02 0x62 0x01>;
   clocks = <0x03 0x62 0x05 0x03 0x62 0x00>;
   clock-names = "hclk", "cclk";
   interrupts = <0x00 0x9b 0x04 0x00 0x9c 0x04>;
   interrupt-names = "int0", "int1";
   bosch,mram-cfg = <0x00 0x80 0x40 0x40 0x40 0x40 0x20 0x20>;
   status = "disabled";
   phandle = <0xa5>;
  };

  can@20711000 {
   compatible = "bosch,m_can";
   reg = <0x00 0x20711000 0x00 0x200 0x00 0x20718000 0x00 0x8000>;
   reg-names = "m_can", "message_ram";
   power-domains = <0x02 0x63 0x01>;
   clocks = <0x03 0x63 0x05 0x03 0x63 0x00>;
   clock-names = "hclk", "cclk";
   interrupts = <0x00 0x9e 0x04 0x00 0x9f 0x04>;
   interrupt-names = "int0", "int1";
   bosch,mram-cfg = <0x00 0x80 0x40 0x40 0x40 0x40 0x20 0x20>;
   status = "disabled";
   phandle = <0xa6>;
  };

  crypto@40900000 {
   compatible = "ti,am64-sa2ul";
   reg = <0x00 0x40900000 0x00 0x1200>;
   power-domains = <0x02 0x85 0x00>;
   #address-cells = <0x02>;
   #size-cells = <0x02>;
   ranges = <0x00 0x40900000 0x00 0x40900000 0x00 0x30000>;
   dmas = <0x07 0xc001 0x00 0x07 0x4002 0x00 0x07 0x4003 0x00>;
   dma-names = "tx", "rx1", "rx2";
   phandle = <0xa7>;

   rng@40910000 {
    compatible = "inside-secure,safexcel-eip76";
    reg = <0x00 0x40910000 0x00 0x7d>;
    interrupts = <0x00 0xa8 0x04>;
    clocks = <0x03 0x85 0x01>;
    status = "disabled";
    phandle = <0xa8>;
   };
  };

  memory-controller@3b000000 {
   compatible = "ti,am64-gpmc";
   power-domains = <0x02 0x50 0x01>;
   clocks = <0x03 0x50 0x00>;
   clock-names = "fck";
   reg = <0x00 0x3b000000 0x00 0x400 0x00 0x50000000 0x00 0x8000000>;
   reg-names = "cfg", "data";
   interrupts = <0x00 0x6a 0x04>;
   gpmc,num-cs = <0x03>;
   gpmc,num-waitpins = <0x02>;
   #address-cells = <0x02>;
   #size-cells = <0x01>;
   interrupt-controller;
   #interrupt-cells = <0x02>;
   gpio-controller;
   #gpio-cells = <0x02>;
   status = "disabled";
   phandle = <0xa9>;
  };

  ecc@25010000 {
   compatible = "ti,am64-elm";
   reg = <0x00 0x25010000 0x00 0x2000>;
   interrupts = <0x00 0x84 0x04>;
   power-domains = <0x02 0x36 0x01>;
   clocks = <0x03 0x36 0x00>;
   clock-names = "fck";
   status = "disabled";
   phandle = <0xaa>;
  };
 };

 clock-cmnrefclk {
  #clock-cells = <0x00>;
  compatible = "fixed-clock";
  clock-frequency = <0x00>;
  phandle = <0x2b>;
 };

 cpus {
  #address-cells = <0x01>;
  #size-cells = <0x00>;

  cpu-map {

   cluster0 {
    phandle = <0xab>;

    core0 {
     cpu = <0x35>;
    };

    core1 {
     cpu = <0x36>;
    };
   };
  };

  cpu@0 {
   compatible = "arm,cortex-a53";
   reg = <0x00>;
   device_type = "cpu";
   enable-method = "psci";
   i-cache-size = <0x8000>;
   i-cache-line-size = <0x40>;
   i-cache-sets = <0x100>;
   d-cache-size = <0x8000>;
   d-cache-line-size = <0x40>;
   d-cache-sets = <0x80>;
   next-level-cache = <0x37>;
   phandle = <0x35>;
  };

  cpu@1 {
   compatible = "arm,cortex-a53";
   reg = <0x01>;
   device_type = "cpu";
   enable-method = "psci";
   i-cache-size = <0x8000>;
   i-cache-line-size = <0x40>;
   i-cache-sets = <0x100>;
   d-cache-size = <0x8000>;
   d-cache-line-size = <0x40>;
   d-cache-sets = <0x80>;
   next-level-cache = <0x37>;
   phandle = <0x36>;
  };
 };

 l2-cache0 {
  compatible = "cache";
  cache-level = <0x02>;
  cache-size = <0x40000>;
  cache-line-size = <0x40>;
  cache-sets = <0x100>;
  phandle = <0x37>;
 };

 memory@80000000 {
  device_type = "memory";
  reg = <0x00 0x80000000 0x00 0x80000000>;
 };

 reserved-memory {
  #address-cells = <0x02>;
  #size-cells = <0x02>;
  ranges;

  optee@9e800000 {
   reg = <0x00 0x9e800000 0x00 0x1800000>;
   alignment = <0x1000>;
   no-map;
   phandle = <0xac>;
  };

  r5f-dma-memory@a0000000 {
   compatible = "shared-dma-pool";
   reg = <0x00 0xa0000000 0x00 0x100000>;
   no-map;
   phandle = <0x1f>;
  };

  r5f-memory@a0100000 {
   compatible = "shared-dma-pool";
   reg = <0x00 0xa0100000 0x00 0xf00000>;
   no-map;
   phandle = <0x20>;
  };

  r5f-dma-memory@a1000000 {
   compatible = "shared-dma-pool";
   reg = <0x00 0xa1000000 0x00 0x100000>;
   no-map;
   phandle = <0x22>;
  };

  r5f-memory@a1100000 {
   compatible = "shared-dma-pool";
   reg = <0x00 0xa1100000 0x00 0xf00000>;
   no-map;
   phandle = <0x23>;
  };

  r5f-dma-memory@a2000000 {
   compatible = "shared-dma-pool";
   reg = <0x00 0xa2000000 0x00 0x100000>;
   no-map;
   phandle = <0x26>;
  };

  r5f-memory@a2100000 {
   compatible = "shared-dma-pool";
   reg = <0x00 0xa2100000 0x00 0xf00000>;
   no-map;
   phandle = <0x27>;
  };

  r5f-dma-memory@a3000000 {
   compatible = "shared-dma-pool";
   reg = <0x00 0xa3000000 0x00 0x100000>;
   no-map;
   phandle = <0x29>;
  };

  r5f-memory@a3100000 {
   compatible = "shared-dma-pool";
   reg = <0x00 0xa3100000 0x00 0xf00000>;
   no-map;
   phandle = <0x2a>;
  };

  ipc-memories@a5000000 {
   reg = <0x00 0xa5000000 0x00 0x800000>;
   alignment = <0x1000>;
   no-map;
   phandle = <0xad>;
  };
 };

 fixed-regulator-vusb-main5v0 {
  compatible = "regulator-fixed";
  regulator-name = "vusb_main5v0";
  regulator-min-microvolt = <0x4c4b40>;
  regulator-max-microvolt = <0x4c4b40>;
  regulator-always-on;
  regulator-boot-on;
  phandle = <0x38>;
 };

 fixedregulator-vcc-3v3-sys {
  compatible = "regulator-fixed";
  regulator-name = "vcc_3v3_sys";
  regulator-min-microvolt = <0x325aa0>;
  regulator-max-microvolt = <0x325aa0>;
  vin-supply = <0x38>;
  regulator-always-on;
  regulator-boot-on;
  phandle = <0x39>;
 };

 fixed-regulator-sd {
  compatible = "regulator-fixed";
  regulator-name = "vdd_mmc1";
  regulator-min-microvolt = <0x325aa0>;
  regulator-max-microvolt = <0x325aa0>;
  regulator-boot-on;
  enable-active-high;
  vin-supply = <0x39>;
  gpio = <0x3a 0x03 0x00>;
  phandle = <0x10>;
 };

 regulator-1 {
  compatible = "regulator-fixed";
  regulator-name = "com8_ls_en";
  regulator-min-microvolt = <0x325aa0>;
  regulator-max-microvolt = <0x325aa0>;
  regulator-always-on;
  regulator-boot-on;
  pinctrl-0 = <0x3b>;
  pinctrl-names = "default";
  gpio = <0x0f 0x3e 0x01>;
  phandle = <0x3d>;
 };

 regulator-2 {
  compatible = "regulator-fixed";
  regulator-name = "wlan_en";
  regulator-min-microvolt = <0x1b7740>;
  regulator-max-microvolt = <0x1b7740>;
  enable-active-high;
  pinctrl-0 = <0x3c>;
  pinctrl-names = "default";
  vin-supply = <0x3d>;
  gpio = <0x0f 0x30 0x00>;
  phandle = <0x0d>;
 };

 led-controller {
  compatible = "gpio-leds";

  led-0 {
   color = <0x02>;
   function = "indicator";
   function-enumerator = <0x01>;
   gpios = <0x3e 0x00 0x00>;
   default-state = "off";
  };

  led-1 {
   color = <0x01>;
   function = "indicator";
   function-enumerator = <0x02>;
   gpios = <0x3e 0x01 0x00>;
   default-state = "off";
  };

  led-2 {
   color = <0x02>;
   function = "indicator";
   function-enumerator = <0x03>;
   gpios = <0x3e 0x02 0x00>;
   default-state = "off";
  };

  led-3 {
   color = <0x04>;
   function = "indicator";
   function-enumerator = <0x04>;
   gpios = <0x3e 0x03 0x00>;
   default-state = "off";
  };

  led-4 {
   color = <0x02>;
   function = "indicator";
   function-enumerator = <0x05>;
   gpios = <0x3e 0x04 0x00>;
   default-state = "off";
  };

  led-5 {
   color = <0x01>;
   function = "indicator";
   function-enumerator = <0x06>;
   gpios = <0x3e 0x05 0x00>;
   default-state = "off";
  };

  led-6 {
   color = <0x02>;
   function = "indicator";
   function-enumerator = <0x07>;
   gpios = <0x3e 0x06 0x00>;
   default-state = "off";
  };

  led-7 {
   color = <0x04>;
   function = "heartbeat";
   function-enumerator = <0x08>;
   linux,default-trigger = "heartbeat";
   gpios = <0x3e 0x07 0x00>;
  };
 };

 __symbols__ {
  psci = "/firmware/psci";
  a53_timer0 = "/timer-cl0-cpu0";
  pmu = "/pmu";
  cbass_main = "/bus@f4000";
  cbass_mcu = "/bus@f4000/bus@4000000";
  mcu_uart0 = "/bus@f4000/bus@4000000/serial@4a00000";
  mcu_uart1 = "/bus@f4000/bus@4000000/serial@4a10000";
  mcu_i2c0 = "/bus@f4000/bus@4000000/i2c@4900000";
  mcu_i2c1 = "/bus@f4000/bus@4000000/i2c@4910000";
  mcu_spi0 = "/bus@f4000/bus@4000000/spi@4b00000";
  mcu_spi1 = "/bus@f4000/bus@4000000/spi@4b10000";
  mcu_gpio_intr = "/bus@f4000/bus@4000000/interrupt-controller@4210000";
  mcu_gpio0 = "/bus@f4000/bus@4000000/gpio@4201000";
  mcu_pmx0 = "/bus@f4000/bus@4000000/pinctrl@4084000";
  oc_sram = "/bus@f4000/sram@70000000";
  main_conf = "/bus@f4000/syscon@43000000";
  serdes_ln_ctrl = "/bus@f4000/syscon@43000000/mux-controller";
  phy_gmii_sel = "/bus@f4000/syscon@43000000/phy@4044";
  epwm_tbclk = "/bus@f4000/syscon@43000000/clock@4140";
  gic500 = "/bus@f4000/interrupt-controller@1800000";
  gic_its = "/bus@f4000/interrupt-controller@1800000/msi-controller@1820000";
  dmss = "/bus@f4000/bus@48000000";
  secure_proxy_main = "/bus@f4000/bus@48000000/mailbox@4d000000";
  inta_main_dmss = "/bus@f4000/bus@48000000/interrupt-controller@48000000";
  main_bcdma = "/bus@f4000/bus@48000000/dma-controller@485c0100";
  main_pktdma = "/bus@f4000/bus@48000000/dma-controller@485c0000";
  dmsc = "/bus@f4000/system-controller@44043000";
  k3_pds = "/bus@f4000/system-controller@44043000/power-controller";
  k3_clks = "/bus@f4000/system-controller@44043000/clock-controller";
  k3_reset = "/bus@f4000/system-controller@44043000/reset-controller";
  main_pmx0 = "/bus@f4000/pinctrl@f4000";
  main_mmc1_pins_default = "/bus@f4000/pinctrl@f4000/main-mmc1-pins-default";
  main_uart0_pins_default = "/bus@f4000/pinctrl@f4000/main-uart0-pins-default";
  main_usb0_pins_default = "/bus@f4000/pinctrl@f4000/main-usb0-pins-default";
  main_i2c1_pins_default = "/bus@f4000/pinctrl@f4000/main-i2c1-pins-default";
  mdio1_pins_default = "/bus@f4000/pinctrl@f4000/mdio1-pins-default";
  rgmii1_pins_default = "/bus@f4000/pinctrl@f4000/rgmii1-pins-default";
  rgmii2_pins_default = "/bus@f4000/pinctrl@f4000/rgmii2-pins-default";
  ospi0_pins_default = "/bus@f4000/pinctrl@f4000/ospi0-pins-default";
  main_ecap0_pins_default = "/bus@f4000/pinctrl@f4000/main-ecap0-pins-default";
  main_wlan_en_pins_default = "/bus@f4000/pinctrl@f4000/main-wlan-en-pins-default";
  main_com8_ls_en_pins_default = "/bus@f4000/pinctrl@f4000/main-com8-ls-en-pins-default";
  main_wlan_pins_default = "/bus@f4000/pinctrl@f4000/main-wlan-pins-default";
  main_uart0 = "/bus@f4000/serial@2800000";
  main_uart1 = "/bus@f4000/serial@2810000";
  main_uart2 = "/bus@f4000/serial@2820000";
  main_uart3 = "/bus@f4000/serial@2830000";
  main_uart4 = "/bus@f4000/serial@2840000";
  main_uart5 = "/bus@f4000/serial@2850000";
  main_uart6 = "/bus@f4000/serial@2860000";
  main_i2c0 = "/bus@f4000/i2c@20000000";
  main_i2c1 = "/bus@f4000/i2c@20010000";
  exp1 = "/bus@f4000/i2c@20010000/gpio@70";
  exp2 = "/bus@f4000/i2c@20010000/gpio@60";
  main_i2c2 = "/bus@f4000/i2c@20020000";
  main_i2c3 = "/bus@f4000/i2c@20030000";
  main_spi0 = "/bus@f4000/spi@20100000";
  main_spi1 = "/bus@f4000/spi@20110000";
  main_spi2 = "/bus@f4000/spi@20120000";
  main_spi3 = "/bus@f4000/spi@20130000";
  main_spi4 = "/bus@f4000/spi@20140000";
  main_gpio_intr = "/bus@f4000/interrupt-controller@a00000";
  main_gpio0 = "/bus@f4000/gpio@600000";
  main_gpio1 = "/bus@f4000/gpio@601000";
  sdhci0 = "/bus@f4000/mmc@fa10000";
  wlcore = "/bus@f4000/mmc@fa10000/wlcore@2";
  sdhci1 = "/bus@f4000/mmc@fa00000";
  cpsw3g = "/bus@f4000/ethernet@8000000";
  cpsw_port1 = "/bus@f4000/ethernet@8000000/ethernet-ports/port@1";
  cpsw_port2 = "/bus@f4000/ethernet@8000000/ethernet-ports/port@2";
  cpsw3g_mdio = "/bus@f4000/ethernet@8000000/mdio@f00";
  cpsw3g_phy0 = "/bus@f4000/ethernet@8000000/mdio@f00/ethernet-phy@0";
  cpsw3g_phy1 = "/bus@f4000/ethernet@8000000/mdio@f00/ethernet-phy@1";
  main_cpts0 = "/bus@f4000/cpts@39000000";
  timesync_router = "/bus@f4000/pinctrl@a40000";
  usbss0 = "/bus@f4000/cdns-usb@f900000";
  usb0 = "/bus@f4000/cdns-usb@f900000/usb@f400000";
  tscadc0 = "/bus@f4000/tscadc@28001000";
  fss = "/bus@f4000/bus@fc00000";
  ospi0 = "/bus@f4000/bus@fc00000/spi@fc40000";
  hwspinlock = "/bus@f4000/spinlock@2a000000";
  mailbox0_cluster2 = "/bus@f4000/mailbox@29020000";
  mbox_main_r5fss0_core0 = "/bus@f4000/mailbox@29020000/mbox-main-r5fss0-core0";
  mbox_main_r5fss0_core1 = "/bus@f4000/mailbox@29020000/mbox-main-r5fss0-core1";
  mailbox0_cluster3 = "/bus@f4000/mailbox@29030000";
  mailbox0_cluster4 = "/bus@f4000/mailbox@29040000";
  mbox_main_r5fss1_core0 = "/bus@f4000/mailbox@29040000/mbox-main-r5fss1-core0";
  mbox_main_r5fss1_core1 = "/bus@f4000/mailbox@29040000/mbox-main-r5fss1-core1";
  mailbox0_cluster5 = "/bus@f4000/mailbox@29050000";
  mailbox0_cluster6 = "/bus@f4000/mailbox@29060000";
  mbox_m4_0 = "/bus@f4000/mailbox@29060000/mbox-m4-0";
  mailbox0_cluster7 = "/bus@f4000/mailbox@29070000";
  main_r5fss0 = "/bus@f4000/r5fss@78000000";
  main_r5fss0_core0 = "/bus@f4000/r5fss@78000000/r5f@78000000";
  main_r5fss0_core1 = "/bus@f4000/r5fss@78000000/r5f@78200000";
  main_r5fss1 = "/bus@f4000/r5fss@78400000";
  main_r5fss1_core0 = "/bus@f4000/r5fss@78400000/r5f@78400000";
  main_r5fss1_core1 = "/bus@f4000/r5fss@78400000/r5f@78600000";
  serdes_wiz0 = "/bus@f4000/wiz@f000000";
  serdes0 = "/bus@f4000/wiz@f000000/serdes@f000000";
  serdes0_usb_link = "/bus@f4000/wiz@f000000/serdes@f000000/phy@0";
  pcie0_rc = "/bus@f4000/pcie@f102000";
  pcie0_ep = "/bus@f4000/pcie-ep@f102000";
  epwm0 = "/bus@f4000/pwm@23000000";
  epwm1 = "/bus@f4000/pwm@23010000";
  epwm2 = "/bus@f4000/pwm@23020000";
  epwm3 = "/bus@f4000/pwm@23030000";
  epwm4 = "/bus@f4000/pwm@23040000";
  epwm5 = "/bus@f4000/pwm@23050000";
  epwm6 = "/bus@f4000/pwm@23060000";
  epwm7 = "/bus@f4000/pwm@23070000";
  epwm8 = "/bus@f4000/pwm@23080000";
  ecap0 = "/bus@f4000/pwm@23100000";
  ecap1 = "/bus@f4000/pwm@23110000";
  ecap2 = "/bus@f4000/pwm@23120000";
  main_rti0 = "/bus@f4000/watchdog@e000000";
  main_rti1 = "/bus@f4000/watchdog@e010000";
  icssg0 = "/bus@f4000/icssg@30000000";
  icssg0_mem = "/bus@f4000/icssg@30000000/memories@0";
  icssg0_cfg = "/bus@f4000/icssg@30000000/cfg@26000";
  icssg0_coreclk_mux = "/bus@f4000/icssg@30000000/cfg@26000/clocks/coreclk-mux@3c";
  icssg0_iepclk_mux = "/bus@f4000/icssg@30000000/cfg@26000/clocks/iepclk-mux@30";
  icssg0_mii_rt = "/bus@f4000/icssg@30000000/mii-rt@32000";
  icssg0_mii_g_rt = "/bus@f4000/icssg@30000000/mii-g-rt@33000";
  icssg0_intc = "/bus@f4000/icssg@30000000/interrupt-controller@20000";
  pru0_0 = "/bus@f4000/icssg@30000000/pru@34000";
  rtu0_0 = "/bus@f4000/icssg@30000000/rtu@4000";
  tx_pru0_0 = "/bus@f4000/icssg@30000000/txpru@a000";
  pru0_1 = "/bus@f4000/icssg@30000000/pru@38000";
  rtu0_1 = "/bus@f4000/icssg@30000000/rtu@6000";
  tx_pru0_1 = "/bus@f4000/icssg@30000000/txpru@c000";
  icssg0_mdio = "/bus@f4000/icssg@30000000/mdio@32400";
  icssg1 = "/bus@f4000/icssg@30080000";
  icssg1_mem = "/bus@f4000/icssg@30080000/memories@0";
  icssg1_cfg = "/bus@f4000/icssg@30080000/cfg@26000";
  icssg1_coreclk_mux = "/bus@f4000/icssg@30080000/cfg@26000/clocks/coreclk-mux@3c";
  icssg1_iepclk_mux = "/bus@f4000/icssg@30080000/cfg@26000/clocks/iepclk-mux@30";
  icssg1_mii_rt = "/bus@f4000/icssg@30080000/mii-rt@32000";
  icssg1_mii_g_rt = "/bus@f4000/icssg@30080000/mii-g-rt@33000";
  icssg1_intc = "/bus@f4000/icssg@30080000/interrupt-controller@20000";
  pru1_0 = "/bus@f4000/icssg@30080000/pru@34000";
  rtu1_0 = "/bus@f4000/icssg@30080000/rtu@4000";
  tx_pru1_0 = "/bus@f4000/icssg@30080000/txpru@a000";
  pru1_1 = "/bus@f4000/icssg@30080000/pru@38000";
  rtu1_1 = "/bus@f4000/icssg@30080000/rtu@6000";
  tx_pru1_1 = "/bus@f4000/icssg@30080000/txpru@c000";
  icssg1_mdio = "/bus@f4000/icssg@30080000/mdio@32400";
  main_mcan0 = "/bus@f4000/can@20701000";
  main_mcan1 = "/bus@f4000/can@20711000";
  crypto = "/bus@f4000/crypto@40900000";
  rng = "/bus@f4000/crypto@40900000/rng@40910000";
  gpmc0 = "/bus@f4000/memory-controller@3b000000";
  elm0 = "/bus@f4000/ecc@25010000";
  serdes_refclk = "/clock-cmnrefclk";
  cluster0 = "/cpus/cpu-map/cluster0";
  cpu0 = "/cpus/cpu@0";
  cpu1 = "/cpus/cpu@1";
  L2_0 = "/l2-cache0";
  secure_ddr = "/reserved-memory/optee@9e800000";
  main_r5fss0_core0_dma_memory_region = "/reserved-memory/r5f-dma-memory@a0000000";
  main_r5fss0_core0_memory_region = "/reserved-memory/r5f-memory@a0100000";
  main_r5fss0_core1_dma_memory_region = "/reserved-memory/r5f-dma-memory@a1000000";
  main_r5fss0_core1_memory_region = "/reserved-memory/r5f-memory@a1100000";
  main_r5fss1_core0_dma_memory_region = "/reserved-memory/r5f-dma-memory@a2000000";
  main_r5fss1_core0_memory_region = "/reserved-memory/r5f-memory@a2100000";
  main_r5fss1_core1_dma_memory_region = "/reserved-memory/r5f-dma-memory@a3000000";
  main_r5fss1_core1_memory_region = "/reserved-memory/r5f-memory@a3100000";
  rtos_ipc_memory_region = "/reserved-memory/ipc-memories@a5000000";
  vusb_main = "/fixed-regulator-vusb-main5v0";
  vcc_3v3_sys = "/fixedregulator-vcc-3v3-sys";
  vdd_mmc1 = "/fixed-regulator-sd";
  com8_ls_en = "/regulator-1";
  wlan_en = "/regulator-2";
 };
};
